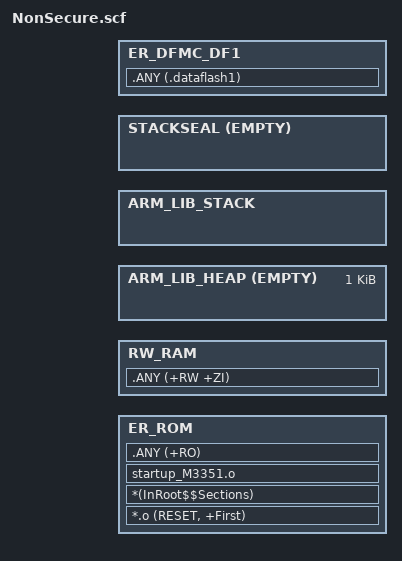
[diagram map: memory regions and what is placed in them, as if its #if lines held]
#! armclang -E --target=arm-arm-none-eabi -mcpu=cortex-m33 -xc
; command above MUST be in first line (no comment above!)

#include "../../partition_M3351.h"

/*
;-------- <<< Use Configuration Wizard in Context Menu >>> -------------------
*/

/*--------------------- Flash Configuration ----------------------------------
; <h> Flash Configuration
;   <o0> Flash Base Address     <0x0-0xFFFFFFFF:8>
;   <o1> Flash Size (in Bytes)  <0x0-0xFFFFFFFF:8>
; </h>
 *----------------------------------------------------------------------------*/
#define FLASH_START         ( 0x10000000 + FMC_SECURE_REGION_SIZE )
#define FLASH_SIZE          ( 0x00100000 - FMC_SECURE_REGION_SIZE )

/*--------------------- Embedded SRAM Configuration --------------------------
; <h> SRAM Configuration
;   <o0> SRAM Base Address      <0x0-0xFFFFFFFF:8>
;   <o1> SRAM Size (in Bytes)   <0x0-0xFFFFFFFF:8>
; </h>
 *----------------------------------------------------------------------------*/
#define SRAM_START          ( 0x30000000 + SCU_SECURE_SRAM_SIZE )
#define SRAM_SIZE           ( 0x00020000 - SCU_SECURE_SRAM_SIZE )

/*--------------------- Stack / Heap Configuration ---------------------------
; <h> Stack / Heap Configuration
;   <o0> Stack Size (in Bytes)  <0x0-0xFFFFFFFF:8>
;   <o1> Heap Size (in Bytes)   <0x0-0xFFFFFFFF:8>
; </h>
 *----------------------------------------------------------------------------*/
#ifndef STACK_SIZE
	#define STACK_SIZE      0x00000400
#endif
	
#ifndef HEAP_SIZE	
	#define HEAP_SIZE       0x00000400
#endif

/*
;-------- <<< End of Use Configuration Section >>> -------------------
*/

#define DFMC_DF1_START      ( 0x1F210000 + DFMC_SECURE_REGION_SIZE )
#define DFMC_DF1_SIZE       ( 0x00010000 - DFMC_SECURE_REGION_SIZE )

/* ----------------------------------------------------------------------------
  Stack seal size definition
 *----------------------------------------------------------------------------*/
#define __STACKSEAL_SIZE   ( 0 )

/*----------------------------------------------------------------------------
  User Stack & Heap boundary definition
 *----------------------------------------------------------------------------*/
#define __STACK_TOP    ( SRAM_START + SRAM_SIZE - __STACKSEAL_SIZE )    /* starts at end of RAM - 8 byte stack seal */
#define __HEAP_BASE    ( AlignExpr(+0, 8))                              /* starts after RW_RAM section, 8 byte aligned */

/*----------------------------------------------------------------------------
  Region base & size definition
 *----------------------------------------------------------------------------*/
#define TZ_NSC_SIZE         ( 0 )

#define __RO_BASE           ( FLASH_START )
#define __RO_SIZE           ( FLASH_SIZE - TZ_NSC_SIZE )

#define __RW_BASE           ( SRAM_START )
#define __RW_SIZE           ( SRAM_SIZE - STACK_SIZE - HEAP_SIZE )

/*----------------------------------------------------------------------------
  Scatter Region definition
 *----------------------------------------------------------------------------*/
LR_ROM __RO_BASE __RO_SIZE  {                       ; load region size_region
    ER_ROM __RO_BASE __RO_SIZE  {                   ; load address = execution address
        *.o (RESET, +First)
        *(InRoot$$Sections)
        ; Make sure reset_handler ends up in root segment
        startup_M3351.o
        .ANY (+RO)
    }

    RW_RAM __RW_BASE __RW_SIZE              ; RW data
    {
        .ANY (+RW +ZI)
    }

#if HEAP_SIZE > 0
    ARM_LIB_HEAP  __HEAP_BASE EMPTY  HEAP_SIZE {}		; Reserve empty region for heap
#endif

    ARM_LIB_STACK __STACK_TOP EMPTY - STACK_SIZE {}     ; Reserve empty region for stack

#if defined (__ARM_FEATURE_CMSE) && (__ARM_FEATURE_CMSE == 3U)
STACKSEAL +0 EMPTY __STACKSEAL_SIZE {
        ; Reserve empty region for stack seal immediately after stack
    }
#endif
}

LR_DFMC_DF1 DFMC_DF1_START DFMC_DF1_SIZE
{
    ER_DFMC_DF1 +0
    {
        .ANY (.dataflash1)
    }
}
